VERSION "VER"

NS_ :

BS_:

BU_: E1

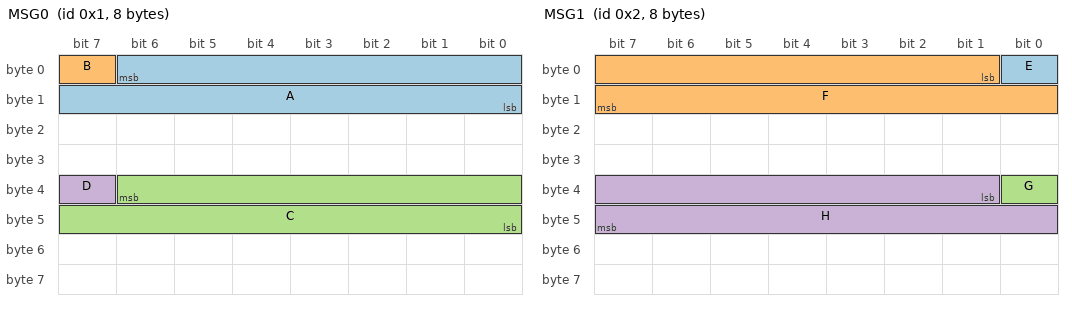
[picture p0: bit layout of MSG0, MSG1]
BO_ 1 MSG0: 8 E1
 SG_ A : 6|15@0+ (1,0) [0|32768] ""  E1
 SG_ B : 7|1@0+ (1,0) [0|1] ""  E1
 SG_ C : 38|15@0+ (1,0) [0|32768] ""  E1
 SG_ D : 39|1@0+ (1,0) [0|1] ""  E1

BO_ 2 MSG1: 8 E1
 SG_ E : 0|1@1+ (1,0) [0|32768] ""  E1
 SG_ F : 1|15@1+ (1,0) [0|32768] ""  E1
 SG_ G : 32|1@1+ (1,0) [0|32768] ""  E1
 SG_ H : 33|15@1+ (1,0) [0|32768] ""  E1

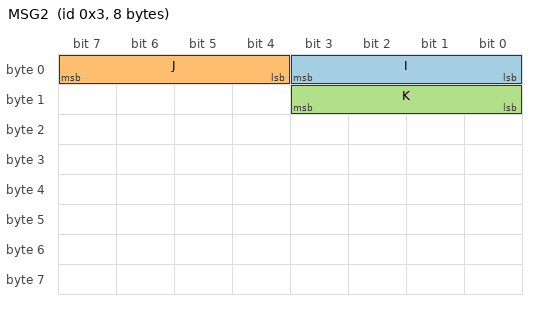
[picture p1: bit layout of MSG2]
BO_ 3 MSG2: 8 E1
 SG_ I : 0|4@1+ (1,0) [0|32768] ""  E1
 SG_ J : 4|4@1+ (1,0) [0|32768] ""  E1
 SG_ K : 8|4@1+ (1,0) [0|32768] ""  E1
